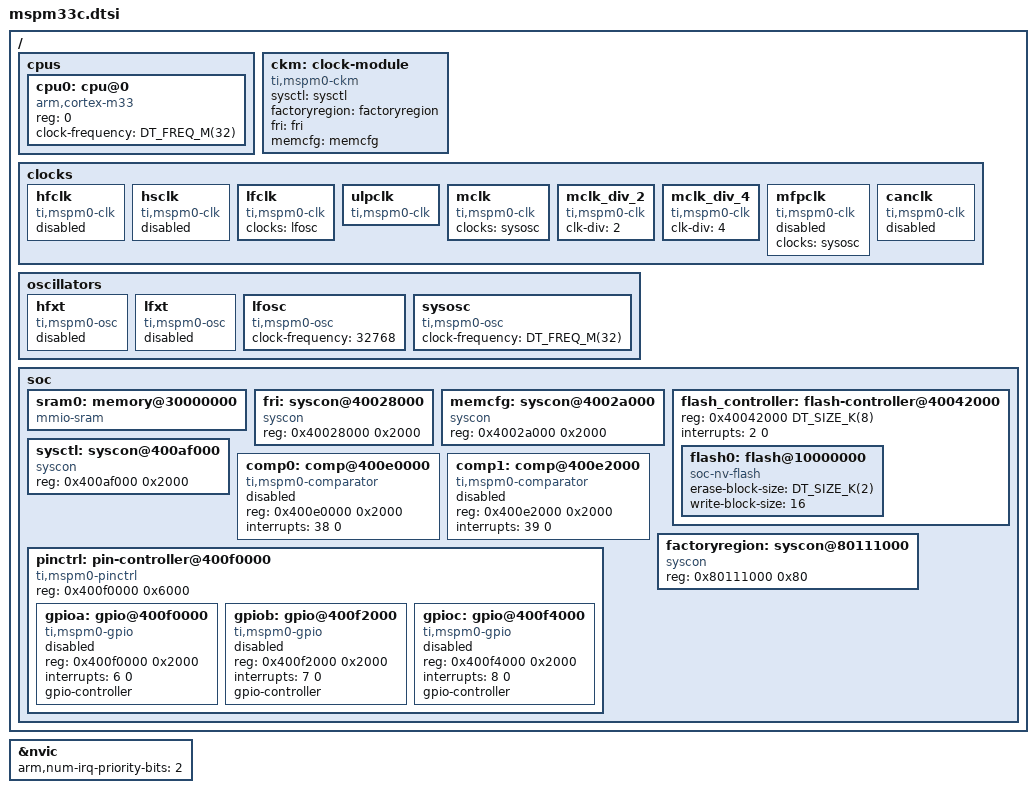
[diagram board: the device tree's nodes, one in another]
/*
 * Copyright (c) 2026 Texas Instruments
 * SPDX-License-Identifier: Apache-2.0
 */

#include <arm/armv8-m.dtsi>
#include <freq.h>
#include <zephyr/dt-bindings/clock/mspm0_clock.h>

/ {
	cpus {
		#address-cells = <1>;
		#size-cells = <0>;

		cpu0: cpu@0 {
			compatible = "arm,cortex-m33";
			reg = <0>;
			device_type = "cpu";
			clock-frequency = <DT_FREQ_M(32)>;
		};
	};

	ckm: clock-module {
		compatible = "ti,mspm0-ckm";
		#clock-cells = <1>;
		sysctl = <&sysctl>;
		factoryregion = <&factoryregion>;
		fri = <&fri>;
		memcfg = <&memcfg>;
	};

	clocks: clocks {
		hfclk: hfclk {
			compatible = "ti,mspm0-clk";
			#clock-cells = <0>;
			status = "disabled";
		};

		hsclk: hsclk {
			compatible = "ti,mspm0-clk";
			#clock-cells = <0>;
			status = "disabled";
		};

		lfclk: lfclk {
			compatible = "ti,mspm0-clk";
			#clock-cells = <0>;
			clocks = <&lfosc>;
		};

		ulpclk: ulpclk {
			compatible = "ti,mspm0-clk";
			#clock-cells = <0>;
		};

		mclk: mclk {
			compatible = "ti,mspm0-clk";
			#clock-cells = <0>;
			clocks = <&sysosc>;
		};

		mclk_div_2: mclk_div_2 {
			compatible = "ti,mspm0-clk";
			#clock-cells = <0>;
			clk-div = <2>;
		};

		mclk_div_4: mclk_div_4 {
			compatible = "ti,mspm0-clk";
			#clock-cells = <0>;
			clk-div = <4>;
		};

		mfpclk: mfpclk {
			compatible = "ti,mspm0-clk";
			#clock-cells = <0>;
			clocks = <&sysosc>;
			status = "disabled";
		};

		canclk: canclk {
			compatible = "ti,mspm0-clk";
			#clock-cells = <0>;
			status = "disabled";
		};
	};

	oscillators: oscillators {
		hfxt: hfxt {
			compatible = "ti,mspm0-osc";
			#clock-cells = <0>;
			status = "disabled";
		};

		lfxt: lfxt {
			compatible = "ti,mspm0-osc";
			#clock-cells = <0>;
			status = "disabled";
		};

		lfosc: lfosc {
			compatible = "ti,mspm0-osc";
			#clock-cells = <0>;
			clock-frequency = <32768>;
		};

		sysosc: sysosc {
			compatible = "ti,mspm0-osc";
			#clock-cells = <0>;
			clock-frequency = <DT_FREQ_M(32)>;
		};
	};

	soc {
		sram0: memory@30000000 {
			compatible = "mmio-sram";
		};

		fri: syscon@40028000 {
			compatible = "syscon";
			reg = <0x40028000 0x2000>;
		};

		memcfg: syscon@4002a000 {
			compatible = "syscon";
			reg = <0x4002a000 0x2000>;
		};

		flash_controller: flash-controller@40042000 {
			reg = <0x40042000 DT_SIZE_K(8)>;
			ranges;
			interrupts = <2 0>;
			#address-cells = <1>;
			#size-cells = <1>;

			flash0: flash@10000000 {
				compatible = "soc-nv-flash";
				erase-block-size = <DT_SIZE_K(2)>;
				write-block-size = <16>;
				#address-cells = <1>;
				#size-cells = <1>;
			};
		};

		sysctl: syscon@400af000 {
			compatible = "syscon";
			reg = <0x400af000 0x2000>;
			status = "okay";
		};

		comp0: comp@400e0000 {
			compatible = "ti,mspm0-comparator";
			reg = <0x400e0000 0x2000>;
			interrupts = <38 0>;
			status = "disabled";
		};

		comp1: comp@400e2000 {
			compatible = "ti,mspm0-comparator";
			reg = <0x400e2000 0x2000>;
			interrupts = <39 0>;
			status = "disabled";
		};

		pinctrl: pin-controller@400f0000 {
			compatible = "ti,mspm0-pinctrl";
			reg = <0x400f0000 0x6000>;
			#address-cells = <1>;
			#size-cells = <1>;

			gpioa: gpio@400f0000 {
				compatible = "ti,mspm0-gpio";
				reg = <0x400f0000 0x2000>;
				interrupts = <6 0>;
				gpio-controller;
				#gpio-cells = <2>;
				status = "disabled";
			};

			gpiob: gpio@400f2000 {
				compatible = "ti,mspm0-gpio";
				reg = <0x400f2000 0x2000>;
				interrupts = <7 0>;
				gpio-controller;
				#gpio-cells = <2>;
				status = "disabled";
			};

			gpioc: gpio@400f4000 {
				compatible = "ti,mspm0-gpio";
				reg = <0x400f4000 0x2000>;
				interrupts = <8 0>;
				gpio-controller;
				#gpio-cells = <2>;
				status = "disabled";
			};
		};

		factoryregion: syscon@80111000 {
			compatible = "syscon";
			reg = <0x80111000 0x80>;
		};
	};
};

&nvic {
	arm,num-irq-priority-bits = <2>;
};
